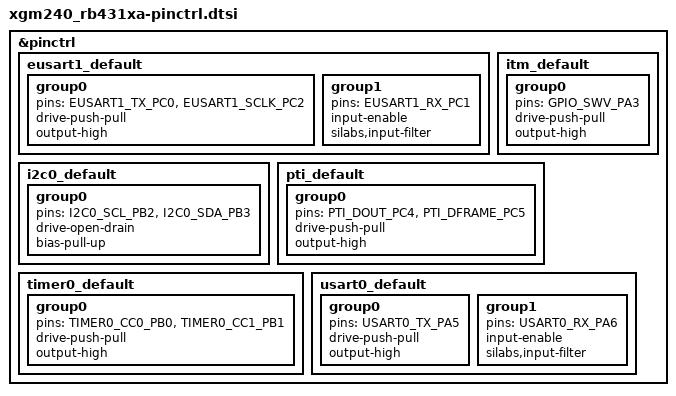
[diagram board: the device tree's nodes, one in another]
/*
 * Copyright (c) 2025 Silicon Laboratories Inc.
 *
 * SPDX-License-Identifier: Apache-2.0
 */

#include <zephyr/dt-bindings/pinctrl/silabs/xg24-pinctrl.h>

&pinctrl {
	eusart1_default: eusart1_default {
		group0 {
			pins = <EUSART1_TX_PC0>, <EUSART1_SCLK_PC2>;
			drive-push-pull;
			output-high;
		};

		group1 {
			pins = <EUSART1_RX_PC1>;
			input-enable;
			silabs,input-filter;
		};
	};

	itm_default: itm_default {
		group0 {
			pins = <GPIO_SWV_PA3>;
			drive-push-pull;
			output-high;
		};
	};

	i2c0_default: i2c0_default {
		group0 {
			pins = <I2C0_SCL_PB2>, <I2C0_SDA_PB3>;
			drive-open-drain;
			bias-pull-up;
		};
	};

	pti_default: pti_default {
		group0 {
			pins = <PTI_DOUT_PC4>, <PTI_DFRAME_PC5>;
			drive-push-pull;
			output-high;
		};
	};

	timer0_default: timer0_default {
		group0 {
			pins = <TIMER0_CC0_PB0>, <TIMER0_CC1_PB1>;
			drive-push-pull;
			output-high;
		};
	};

	usart0_default: usart0_default {
		group0 {
			pins = <USART0_TX_PA5>;
			drive-push-pull;
			output-high;
		};

		group1 {
			pins = <USART0_RX_PA6>;
			input-enable;
			silabs,input-filter;
		};
	};
};
